# AT32UC3B0512 device description
Architecture: AVR32_UC3; Family: AVR UC3
Registers are 32-bit, read-write, reset 0x0 unless marked. A register's access mark holds for its fields unless they carry their own. Offsets are from the block's base; [hi:lo] are bit positions; lines under a group give offsets from that group; {n}, {i} and the like mark numbered series; 'fields as' and 'values as' point back to an identical list.

## EIC — External Interrupt Controller
Instances: EIC 0xffff0d80
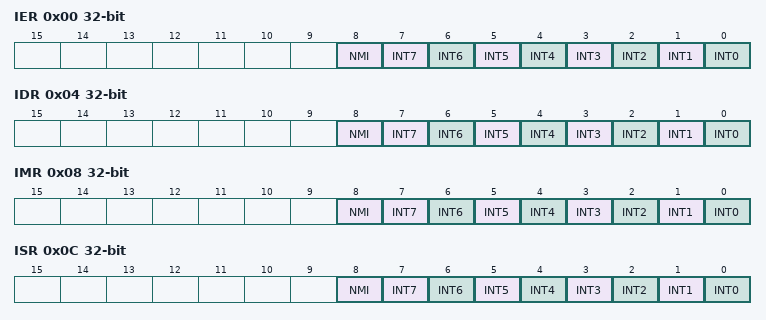
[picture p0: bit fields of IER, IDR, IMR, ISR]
0x00 IER wo — Interrupt Enable Register
  [8] NMI — External Non Maskable CPU interrupt
  [n] INT{n} (n=0..7) — External Interrupt {n}
0x04 IDR wo — Interrupt Disable Register
  fields as IER
0x08 IMR ro — Interrupt Mask Register
  fields as IER
0x0C ISR ro — Interrupt Status Register
  fields as IER
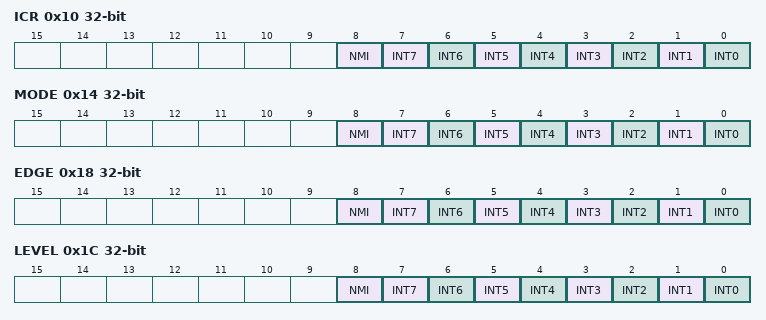
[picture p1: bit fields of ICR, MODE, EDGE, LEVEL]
0x10 ICR wo — Interrupt Clear Register
  fields as IER
0x14 MODE
  fields as IER
0x18 EDGE
  fields as IER
0x1C LEVEL
  fields as IER
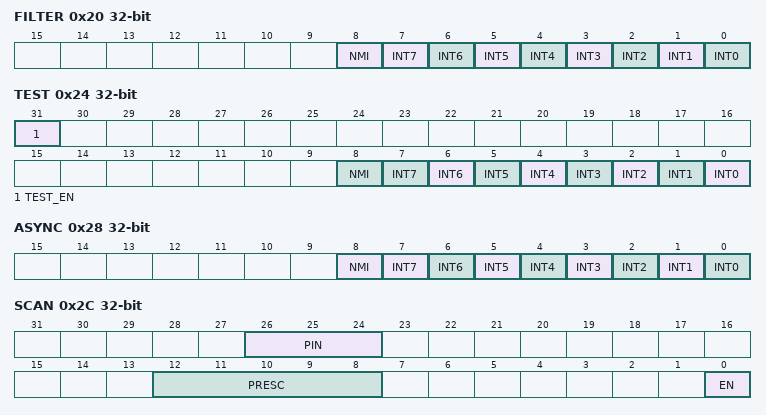
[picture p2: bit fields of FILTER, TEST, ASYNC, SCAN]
0x20 FILTER
  fields as IER
0x24 TEST
  [31] TEST_EN — Test Enable
  [8] NMI — External Non Maskable CPU interrupt
  [n] INT{n} (n=0..7) — External Interrupt {n}
0x28 ASYNC — Asynchronous Mode Register
  fields as IER
0x2C SCAN
  [26:24] PIN — SCAN Pin
  [12:8] PRESC — SCAN Prescale
  [0] EN — SCAN Enable
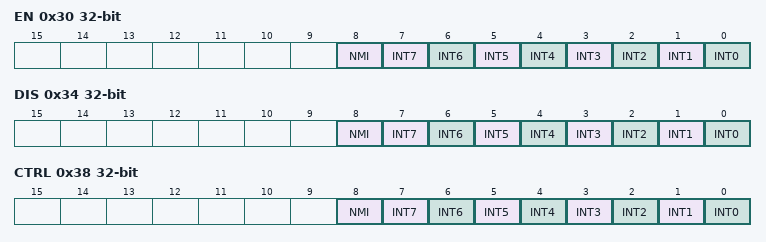
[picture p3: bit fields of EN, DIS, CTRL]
0x30 EN wo — Enable Register
  fields as IER
0x34 DIS wo — Disable Register
  fields as IER
0x38 CTRL — Control Register
  fields as IER

## FLASHC — Flash Controller
Instances: FLASHC 0xfffe1400
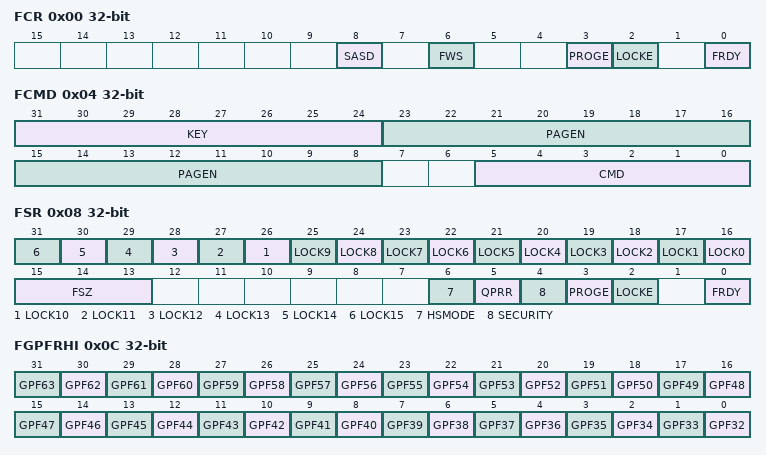
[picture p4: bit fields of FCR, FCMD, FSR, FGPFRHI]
0x00 FCR — Flash Controller Control Register
  [8] SASD, [6] FWS, [3] PROGE, [2] LOCKE, [0] FRDY
0x04 FCMD — Flash Controller Command Register
  [31:24] KEY
    165=KEY
  [23:8] PAGEN
  [5:0] CMD — Command
    0=NOP; 1=WP; 2=EP; 3=CPB; 4=LP; 5=UP; 6=EA; 7=WGPB; 8=EGPB; 9=SSB; 10=PGPFB; 11=EAGPF; 12=QPR; 13=WUP; 14=EUP; 15=QPRUP; 16=HSEN; 17=HSDIS
0x08 FSR reset not defined — Flash Controller Status Register
  [n+16] LOCK{n} (n=0..15)
  [15:13] FSZ
    0=32; 1=64; 2=128; 3=256; 4=384; 5=512; 6=768; 7=1024
  [6] HSMODE
  [5] QPRR
  [4] SECURITY
  [3] PROGE
  [2] LOCKE
  [0] FRDY
0x0C FGPFRHI ro reset not defined — Flash Controller General Purpose Fuse Register High
  [n-32] GPF{n} (n=32..63)
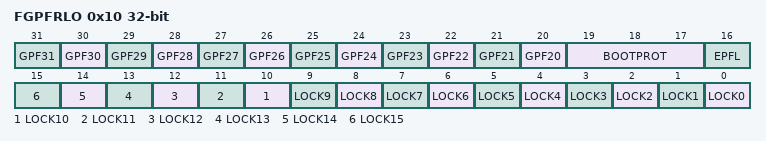
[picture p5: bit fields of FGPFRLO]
0x10 FGPFRLO ro reset not defined — Flash Controller General Purpose Fuse Register Low
  [n] GPF{n} (n=20..31), [19:17] BOOTPROT, [16] EPFL, [n] LOCK{n} (n=0..15)

## FREQM — Frequency Meter
Instances: FREQM 0xffff0d50
0x00 CTRL wo — Frequency Meter Control register
  [0] START — Start frequency measurement
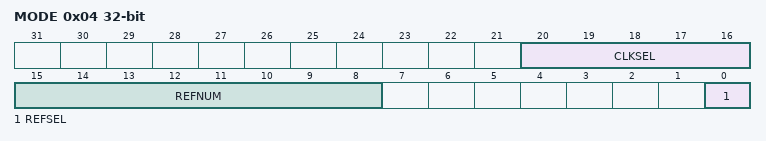
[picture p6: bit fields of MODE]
0x04 MODE — Frequency Meter Mode register
  [20:16] CLKSEL — Select the measured clock
    0=CPU; 1=HSB; 2=PBA; 3=PBB; 4=OSC0; 5=OSC1; 6=OSC32; 7=RCOSC; 8=PLL0; 9=PLL1; 10=CRIPLEL; {v}=GENCLK{v-11} (v=11..16)
  [15:8] REFNUM — Select the number of period of reference clock that will be used to measure frequency
  [0] REFSEL — Select reference clock
    0=REF_RCOSC; 1=REF_OSC32
0x08 STATUS ro — Frequency Meter Status register
  [0] BUSY — Frequency measurement on-going
0x0C VALUE — Frequency Meter Value register
  [23:0] VALUE — Measured frequency
0x10 IER wo — Frequency Meter Interrupt Enable Register
  [0] DONE — Frequency measurment done
0x14 IDR wo — Frequency Meter Interrupt Diable Register
  [0] DONE — Frequency measurment done
0x18 IMR ro — Frequency Meter Interrupt Mask Register
  [0] DONE — Frequency measurment done
0x1C ISR ro — Frequency Meter Interrupt Status Register
  [0] DONE — Frequency measurment done
0x20 ICR wo — Frequency Meter Interrupt Clear Register
  [0] DONE — Frequency measurment done

## GPIO — General Purpose Input/Output
Instances: GPIO 0xffff1000
{0x0+0x100*i} port[{i}] (i=0..63) group
  0x00 GPER — GPIO Enable Register
  0x04 GPERS wo reset not defined — GPIO Enable Register - Set
  0x08 GPERC wo reset not defined — GPIO Enable Register - Clear
  0x0C GPERT wo reset not defined — GPIO Enable Register - Toggle
  0x10 PMR0 — Peripheral Mux Register 0
  0x14 PMR0S wo reset not defined — Peripheral Mux Register 0 - Set
  0x18 PMR0C wo reset not defined — Peripheral Mux Register 0 - Clear
  0x1C PMR0T wo reset not defined — Peripheral Mux Register 0 - Toggle
  0x20 PMR1 — Peripheral Mux Register 1
  0x24 PMR1S wo reset not defined — Peripheral Mux Register 1 - Set
  0x28 PMR1C wo reset not defined — Peripheral Mux Register 1 - Clear
  0x2C PMR1T wo reset not defined — Peripheral Mux Register 1 - Toggle
  0x40 ODER — Output Driver Enable Register
  0x44 ODERS wo reset not defined — Output Driver Enable Register - Set
  0x48 ODERC wo reset not defined — Output Driver Enable Register - Clear
  0x4C ODERT wo reset not defined — Output Driver Enable Register - Toggle
  0x50 OVR — Output Value Register
  0x54 OVRS wo reset not defined — Output Value Register - Set
  0x58 OVRC wo reset not defined — Output Value Register - Clear
  0x5C OVRT wo reset not defined — Output Value Register - Toggle
  0x60 PVR ro — Pin Value Register
  0x70 PUER — Pull-up Enable Register
  0x74 PUERS wo reset not defined — Pull-up Enable Register - Set
  0x78 PUERC wo reset not defined — Pull-up Enable Register - Clear
  0x7C PUERT wo reset not defined — Pull-up Enable Register - Toggle
  0x80 ODMER — Open Drain Mode Register
  0x84 ODMERS wo reset not defined — Open Drain Mode Register - Set
  0x88 ODMERC wo reset not defined — Open Drain Mode Register - Clear
  0x8C ODMERT wo reset not defined — Open Drain Mode Register - Toggle
  0x90 IER — Interrupt Enable Register
  0x94 IERS wo reset not defined — Interrupt Enable Register - Set
  0x98 IERC wo reset not defined — Interrupt Enable Register - Clear
  0x9C IERT wo reset not defined — Interrupt Enable Register - Toggle
  0xA0 IMR0 — Interrupt Mode Register 0
  0xA4 IMR0S wo reset not defined — Interrupt Mode Register 0 - Set
  0xA8 IMR0C wo reset not defined — Interrupt Mode Register 0 - Clear
  0xAC IMR0T wo reset not defined — Interrupt Mode Register 0 - Toggle
  0xB0 IMR1 — Interrupt Mode Register 1
  0xB4 IMR1S wo reset not defined — Interrupt Mode Register 1 - Set
  0xB8 IMR1C wo reset not defined — Interrupt Mode Register 1 - Clear
  0xBC IMR1T wo reset not defined — Interrupt Mode Register 1 - Toggle
  0xC0 GFER — Glitch Filter Enable Register
  0xC4 GFERS wo reset not defined — Glitch Filter Enable Register - Set
  0xC8 GFERC wo reset not defined — Glitch Filter Enable Register - Clear
  0xCC GFERT wo reset not defined — Glitch Filter Enable Register - Toggle
  0xD0 IFR ro — Interrupt Flag Register
  0xD8 IFRC wo reset not defined — Interrupt Flag Register - Clear
